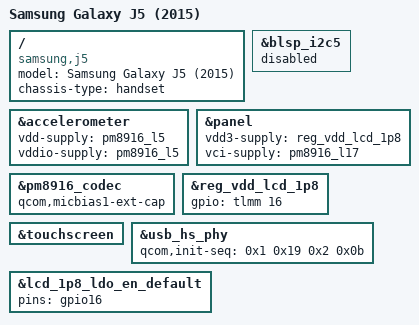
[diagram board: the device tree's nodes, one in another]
// SPDX-License-Identifier: GPL-2.0-only

/dts-v1/;

#include "msm8916-samsung-j5-common.dtsi"

/ {
	model = "Samsung Galaxy J5 (2015)";
	compatible = "samsung,j5", "qcom,msm8916";
	chassis-type = "handset";
};

&accelerometer {
	vdd-supply = <&pm8916_l5>;
	vddio-supply = <&pm8916_l5>;
};

&blsp_i2c5 {
	status = "disabled";
};

&panel {
	vdd3-supply = <&reg_vdd_lcd_1p8>;
	vci-supply = <&pm8916_l17>;
};

&pm8916_codec {
	qcom,micbias1-ext-cap;
};

&reg_vdd_lcd_1p8 {
	gpio = <&tlmm 16 GPIO_ACTIVE_HIGH>;
	status = "okay";
};

&touchscreen {
	/* FIXME: Missing sm5703-mfd driver to power up vdd-supply */
};

&usb_hs_phy {
	qcom,init-seq = /bits/ 8 <0x1 0x19 0x2 0x0b>;
};

&lcd_1p8_ldo_en_default {
	pins = "gpio16";
};
